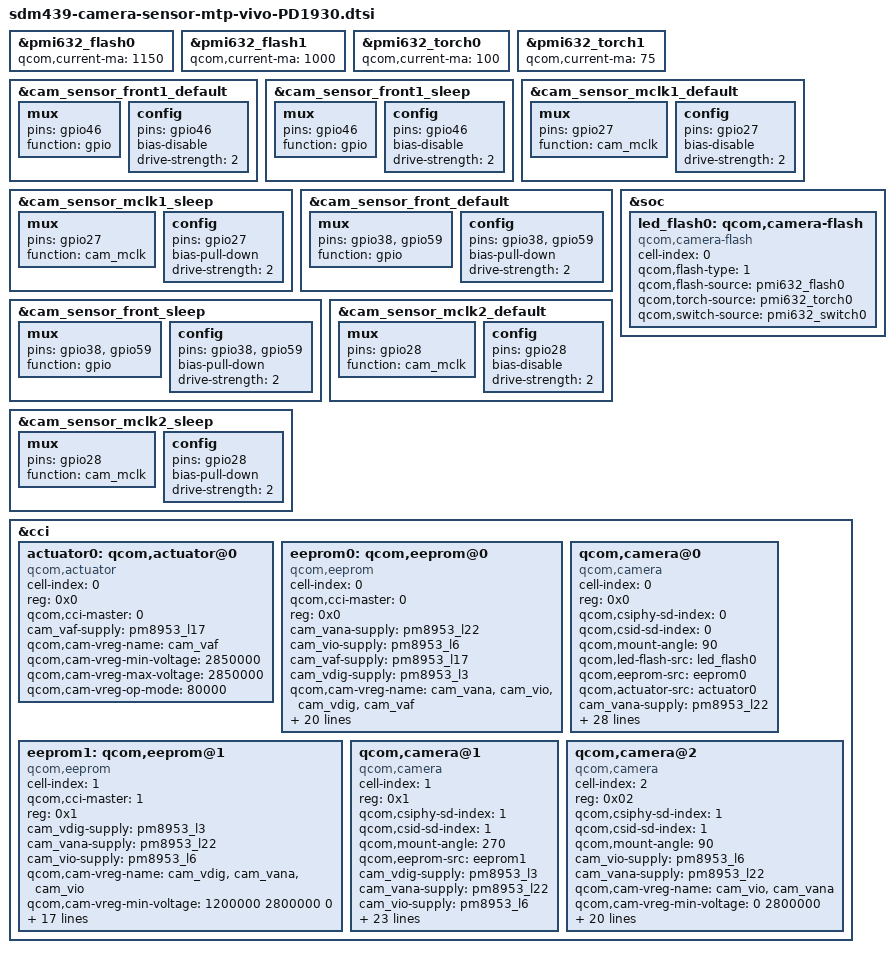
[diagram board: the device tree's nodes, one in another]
/*
 * Copyright (c) 2015-2016, 2018, The Linux Foundation. All rights reserved.
 *
 * This program is free software; you can redistribute it and/or modify
 * it under the terms of the GNU General Public License version 2 and
 * only version 2 as published by the Free Software Foundation.
 *
 * This program is distributed in the hope that it will be useful,
 * but WITHOUT ANY WARRANTY; without even the implied warranty of
 * MERCHANTABILITY or FITNESS FOR A PARTICULAR PURPOSE.  See the
 * GNU General Public License for more details.
 */

#include <dt-bindings/clock/msm-clocks-8952.h>

&pmi632_flash0 {
	qcom,current-ma = <1150>;
};

&pmi632_flash1 {
	qcom,current-ma = <1000>;
};

&pmi632_torch0 {
	qcom,current-ma = <100>;
};

&pmi632_torch1 {
	qcom,current-ma = <75>;
};

&cam_sensor_front1_default {
	/* RESET */
	mux {
		pins = "gpio46";
		function = "gpio";
	};

	config {
		pins = "gpio46";
		bias-disable; /* No PULL */
		drive-strength = <2>; /* 2 MA */
	};
};

&cam_sensor_front1_sleep {
	/* RESET */
	mux {
		pins = "gpio46";
		function = "gpio";
	};

	config {
		pins = "gpio46";
		bias-disable; /* No PULL */
		drive-strength = <2>; /* 2 MA */
	};
};

&cam_sensor_mclk1_default {
	/* MCLK1 */
	mux {
		/* CLK, DATA */
		pins = "gpio27";
		function = "cam_mclk";
	};

	config {
		pins = "gpio27";
		bias-disable; /* No PULL */
		drive-strength = <2>; /* 2 MA */
	};
};

&cam_sensor_mclk1_sleep {
	/* MCLK1 */
	mux {
		/* CLK, DATA */
		pins = "gpio27";
		function = "cam_mclk";
	};

	config {
		pins = "gpio27";
		bias-pull-down; /* PULL DOWN */
		drive-strength = <2>; /* 2 MA */
	};
};

&cam_sensor_front_default {
	/* RESET , VSYNC*/
	mux {
		pins = "gpio38","gpio59";
		function = "gpio";
	};

	config {
		pins = "gpio38","gpio59";
		bias-pull-down; /*PULL DOWN*/
		drive-strength = <2>; /* 2 MA */
	};
};

&cam_sensor_front_sleep {
	/* RESET , VSYNC*/
	mux {
		pins = "gpio38","gpio59";
		function = "gpio";
	};

	config {
		pins = "gpio38","gpio59";
		bias-pull-down; /*PULL DOWN*/
		drive-strength = <2>; /* 2 MA */
	};
};

&cam_sensor_mclk2_default {
	/* MCLK2 */
	mux {
		/* CLK, DATA */
		pins = "gpio28";
		function = "cam_mclk";
	};

	config {
		pins = "gpio28";
		bias-disable; /* No PULL */
		drive-strength = <2>; /* 2 MA */
	};
};

&cam_sensor_mclk2_sleep {
	/* MCLK2 */
	mux {
		/* CLK, DATA */
		pins = "gpio28";
		function = "cam_mclk";
	};

	config {
		pins = "gpio28";
		bias-pull-down; /* PULL DOWN */
		drive-strength = <2>; /* 2 MA */
	};
};

&soc {
	led_flash0: qcom,camera-flash {
		cell-index = <0>;
		compatible = "qcom,camera-flash";
		qcom,flash-type = <1>;
		qcom,flash-source = <&pmi632_flash0>;
		qcom,torch-source = <&pmi632_torch0>;
		qcom,switch-source = <&pmi632_switch0>;
		status = "ok";
	};
};

&cci {
	actuator0: qcom,actuator@0 {
		cell-index = <0>;
		reg = <0x0>;
		compatible = "qcom,actuator";
		qcom,cci-master = <0>;
		cam_vaf-supply = <&pm8953_l17>;
		qcom,cam-vreg-name = "cam_vaf";
		qcom,cam-vreg-min-voltage = <2850000>;
		qcom,cam-vreg-max-voltage = <2850000>;
		qcom,cam-vreg-op-mode = <80000>;
	};

	eeprom0: qcom,eeprom@0 {
		cell-index = <0>;
		compatible = "qcom,eeprom";
		qcom,cci-master = <0>;
		reg = <0x0>;
		cam_vana-supply = <&pm8953_l22>;
		cam_vio-supply = <&pm8953_l6>;
		cam_vaf-supply = <&pm8953_l17>;
		cam_vdig-supply = <&pm8953_l3>;
		qcom,cam-vreg-name = "cam_vana",
			"cam_vio", "cam_vdig", "cam_vaf";
		qcom,cam-vreg-min-voltage = <2800000 0 1200000 2850000>;
		qcom,cam-vreg-max-voltage = <2800000 0 1200000 2850000>;
		qcom,cam-vreg-op-mode = <80000 0 200000 100000>;
		pinctrl-names = "cam_default", "cam_suspend";
		pinctrl-0 = <&cam_sensor_mclk0_default
				&cam_sensor_rear_reset
			&cam_sensor_rear_vana>;
		pinctrl-1 = <&cam_sensor_mclk0_sleep
			&cam_sensor_rear_reset_sleep
			&cam_sensor_rear_vana_sleep>;
		gpios = <&tlmm 26 0>,
			<&tlmm 36 0>,
			<&tlmm 35 0>;
		qcom,gpio-reset = <1>;
		qcom,gpio-vana = <2>;
		qcom,gpio-req-tbl-num = <0 1 2>;
		qcom,gpio-req-tbl-flags = <1 0 2>;
		qcom,gpio-req-tbl-label = "CAMIF_MCLK0",
			"CAM_RESET0",
			"CAM_VANA";
		status = "ok";
		clocks = <&clock_gcc clk_mclk0_clk_src>,
			<&clock_gcc clk_gcc_camss_mclk0_clk>;
		clock-names = "cam_src_clk", "cam_clk";
		qcom,clock-rates = <24000000 0>;
	};
	
	eeprom1: qcom,eeprom@1 {
		cell-index = <1>;
		compatible = "qcom,eeprom";
		qcom,cci-master = <1>;
		reg = <0x1>;
		cam_vdig-supply = <&pm8953_l3>;
		cam_vana-supply = <&pm8953_l22>;
		cam_vio-supply = <&pm8953_l6>;
		qcom,cam-vreg-name = "cam_vdig", "cam_vana", "cam_vio";
		qcom,cam-vreg-min-voltage = <1200000 2800000 0>;
		qcom,cam-vreg-max-voltage = <1200000 2800000 0>;
		qcom,cam-vreg-op-mode = <200000 80000 0>;
		pinctrl-names = "cam_default", "cam_suspend";
		pinctrl-0 = <&cam_sensor_mclk1_default
				&cam_sensor_front_default>;
		pinctrl-1 = <&cam_sensor_mclk1_sleep
				&cam_sensor_front_sleep>;
		gpios = <&tlmm 27 0>,
			<&tlmm 38 0>,
			<&tlmm 35 0>,
			<&tlmm 44 0>;
		qcom,gpio-reset = <1>;
		qcom,gpio-vana = <2>;
		qcom,gpio-vdig = <3>;
		qcom,gpio-req-tbl-num = <0 1 2 3>;
		qcom,gpio-req-tbl-flags = <1 0 2 0>;
		qcom,gpio-req-tbl-label = "CAMIF_MCLK1",
			"CAM_RESET1",
			"CAM_VANA1",
			"CAM_VDIG1";
		status = "ok";
		clocks = <&clock_gcc clk_mclk1_clk_src>,
				<&clock_gcc clk_gcc_camss_mclk1_clk>;
		clock-names = "cam_src_clk", "cam_clk";
		qcom,clock-rates = <24000000 0>;
	};

	
	qcom,camera@0 {
		cell-index = <0>;
		compatible = "qcom,camera";
		reg = <0x0>;
		qcom,csiphy-sd-index = <0>;
		qcom,csid-sd-index = <0>;
		qcom,mount-angle = <90>;
		qcom,led-flash-src = <&led_flash0>;
		qcom,eeprom-src = <&eeprom0>;
		qcom,actuator-src = <&actuator0>;
		cam_vana-supply = <&pm8953_l22>;
		cam_vio-supply = <&pm8953_l6>;
		cam_vaf-supply = <&pm8953_l17>;
		cam_vdig-supply = <&pm8953_l3>;
		qcom,cam-vreg-name = "cam_vana",
			"cam_vio", "cam_vaf", "cam_vdig";
		qcom,cam-vreg-min-voltage = <2800000 0 2850000 1200000>;
		qcom,cam-vreg-max-voltage = <2800000 0 2850000 1200000>;
		qcom,cam-vreg-op-mode = <80000 0 200000 100000>;
		pinctrl-names = "cam_default", "cam_suspend";
		pinctrl-0 = <&cam_sensor_mclk0_default
				&cam_sensor_rear_reset
				&cam_sensor_rear_vana>;
		pinctrl-1 = <&cam_sensor_mclk0_sleep
				&cam_sensor_rear_reset_sleep
				&cam_sensor_rear_vana_sleep>;
		gpios = <&tlmm 26 0>,
			<&tlmm 36 0>,
			<&tlmm 35 0>;
		qcom,gpio-reset = <1>;
		qcom,gpio-vana = <2>;
		qcom,gpio-req-tbl-num = <0 1 2>;
		qcom,gpio-req-tbl-flags = <1 0 2>;
		qcom,gpio-req-tbl-label = "CAMIF_MCLK0",
			"CAM_RESET0",
			"CAM_VANA0";
		qcom,sensor-position = <0>;
		qcom,sensor-mode = <0>;
		qcom,cci-master = <0>;
		status = "ok";
		clocks = <&clock_gcc clk_mclk0_clk_src>,
				<&clock_gcc clk_gcc_camss_mclk0_clk>;
		clock-names = "cam_src_clk", "cam_clk";
		qcom,clock-rates = <24000000 0>;
	};

	qcom,camera@1 {
		cell-index = <1>;
		compatible = "qcom,camera";
		reg = <0x1>;
		qcom,csiphy-sd-index = <1>;
		qcom,csid-sd-index = <1>;
		qcom,mount-angle = <270>;
		//qcom,led-flash-src = <&led_flash1>;
		qcom,eeprom-src = <&eeprom1>;
		cam_vdig-supply = <&pm8953_l3>;
		cam_vana-supply = <&pm8953_l22>;
		cam_vio-supply = <&pm8953_l6>;
		qcom,cam-vreg-name = "cam_vdig", "cam_vana", "cam_vio";
		qcom,cam-vreg-min-voltage = <1275000 2800000 0>;
		qcom,cam-vreg-max-voltage = <1275000 2800000 0>;
		qcom,cam-vreg-op-mode = <200000 80000 0>;
		pinctrl-names = "cam_default", "cam_suspend";
		pinctrl-0 = <&cam_sensor_mclk1_default
				&cam_sensor_front_default>;
		pinctrl-1 = <&cam_sensor_mclk1_sleep
				&cam_sensor_front_sleep>;
		gpios = <&tlmm 27 0>,
			<&tlmm 38 0>,
			<&tlmm 35 0>,
			<&tlmm 44 0>;
		qcom,gpio-reset = <1>;
		qcom,gpio-vana = <2>;
		qcom,gpio-vdig = <3>;
		qcom,gpio-req-tbl-num = <0 1 2 3>;
		qcom,gpio-req-tbl-flags = <1 0 2 0>;
		qcom,gpio-req-tbl-label = "CAMIF_MCLK1",
			"CAM_RESET1",
			"CAM_VANA1",
			"CAM_VDIG1";
		qcom,sensor-position = <1>;
		qcom,sensor-mode = <1>;
		qcom,cci-master = <1>;
		clocks = <&clock_gcc clk_mclk1_clk_src>,
				<&clock_gcc clk_gcc_camss_mclk1_clk>;
		clock-names = "cam_src_clk", "cam_clk";
		qcom,clock-rates = <24000000 0>;
	};

	qcom,camera@2 {
		cell-index = <2>;
		compatible = "qcom,camera";
		reg = <0x02>;
		qcom,csiphy-sd-index = <1>;
		qcom,csid-sd-index = <1>;
		qcom,mount-angle = <90>;
		cam_vio-supply = <&pm8953_l6>;
		cam_vana-supply = <&pm8953_l22>;
		qcom,cam-vreg-name = "cam_vio", "cam_vana";
		qcom,cam-vreg-min-voltage = <0 2800000>;
		qcom,cam-vreg-max-voltage = <0 2800000>;
		qcom,cam-vreg-op-mode = <0 80000>;
		qcom,gpio-no-mux = <0>;
		pinctrl-names = "cam_default", "cam_suspend";
		pinctrl-0 = <&cam_sensor_mclk2_default
				&cam_sensor_front1_default>;
		pinctrl-1 = <&cam_sensor_mclk2_sleep
				&cam_sensor_front1_sleep>;
		gpios = <&tlmm 28 0>,
			<&tlmm 46 0>,
			<&tlmm 50 0>;
		qcom,gpio-reset = <1>;
		qcom,gpio-vana = <2>;
		qcom,gpio-req-tbl-num = <0 1 2>;
		qcom,gpio-req-tbl-flags = <1 0 0>;
		qcom,gpio-req-tbl-label = "CAMIF_MCLK2",
					  "CAM_RESET2",
					  "CAM_VANA2";
		qcom,sensor-position = <0>;
		qcom,sensor-mode = <0>;
		qcom,cci-master = <1>;
		status = "ok";
		clocks = <&clock_gcc clk_mclk2_clk_src>,
			<&clock_gcc clk_gcc_camss_mclk2_clk>;
		clock-names = "cam_src_clk", "cam_clk";
		qcom,clock-rates = <24000000 0>;
	};
};
